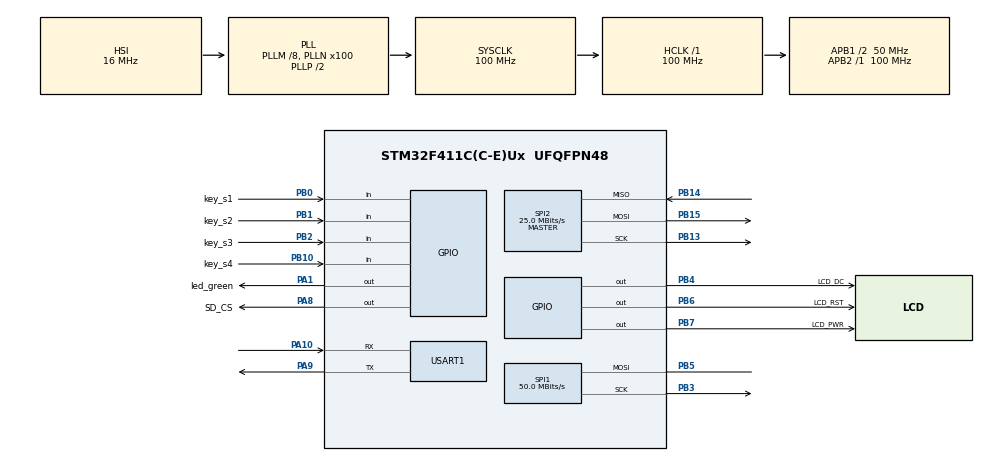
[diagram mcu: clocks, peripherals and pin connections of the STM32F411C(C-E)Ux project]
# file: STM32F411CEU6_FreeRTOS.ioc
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Mcu.Family=STM32F4
Mcu.Name=STM32F411C(C-E)Ux
Mcu.Package=UFQFPN48
NVIC.PriorityGroup=NVIC_PRIORITYGROUP_4
PA1.GPIO_Label=led_green
PA1.Signal=GPIO_Output
PA10.Mode=Asynchronous
PA10.Signal=USART1_RX
PA13.Mode=Serial_Wire
PA13.Signal=SYS_JTMS-SWDIO
PA14.Mode=Serial_Wire
PA14.Signal=SYS_JTCK-SWCLK
PA8.GPIO_Label=SD_CS
PA8.Signal=GPIO_Output
PA9.Mode=Asynchronous
PA9.Signal=USART1_TX
PB0.GPIO_Label=key_s1
PB0.GPIO_PuPd=GPIO_PULLDOWN
PB0.Signal=GPIO_Input
PB1.GPIO_Label=key_s2
PB1.GPIO_PuPd=GPIO_PULLDOWN
PB1.Signal=GPIO_Input
PB10.GPIO_Label=key_s4
PB10.GPIO_PuPd=GPIO_PULLDOWN
PB10.Signal=GPIO_Input
PB13.Mode=Full_Duplex_Master
PB13.Signal=SPI2_SCK
PB14.Mode=Full_Duplex_Master
PB14.Signal=SPI2_MISO
PB15.Mode=Full_Duplex_Master
PB15.Signal=SPI2_MOSI
PB2.GPIO_Label=key_s3
PB2.GPIO_PuPd=GPIO_PULLDOWN
PB2.Signal=GPIO_Input
PB3.Mode=Simplex_Bidirectional_Master
PB3.Signal=SPI1_SCK
PB4.GPIO_Label=LCD_DC
PB4.Signal=GPIO_Output
PB5.Mode=Simplex_Bidirectional_Master
PB5.Signal=SPI1_MOSI
PB6.GPIO_Label=LCD_RST
PB6.Signal=GPIO_Output
PB7.GPIO_Label=LCD_PWR
PB7.Signal=GPIO_Output
PH0\ -\ OSC_IN.Mode=HSE-External-Oscillator
PH0\ -\ OSC_IN.Signal=RCC_OSC_IN
PH1\ -\ OSC_OUT.Mode=HSE-External-Oscillator
PH1\ -\ OSC_OUT.Signal=RCC_OSC_OUT
ProjectManager.HeapSize=0x200
ProjectManager.StackSize=0x400
ProjectManager.TargetToolchain=MDK-ARM V5.27
RCC.48MHZClocksFreq_Value=50000000
RCC.AHBFreq_Value=100000000
RCC.APB1CLKDivider=RCC_HCLK_DIV2
RCC.APB1Freq_Value=50000000
RCC.APB1TimFreq_Value=100000000
RCC.APB2Freq_Value=100000000
RCC.APB2TimFreq_Value=100000000
RCC.CortexFreq_Value=100000000
RCC.HCLKFreq_Value=100000000
RCC.HSE_VALUE=12000000
RCC.HSI_VALUE=16000000
RCC.LSE_VALUE=32768
RCC.PLLM=8
RCC.PLLN=100
RCC.SYSCLKFreq_VALUE=100000000
RCC.SYSCLKSource=RCC_SYSCLKSOURCE_PLLCLK
RCC.VCOOutputFreq_Value=200000000
SPI1.CLKPhase=SPI_PHASE_2EDGE
SPI1.CLKPolarity=SPI_POLARITY_HIGH
SPI1.CalculateBaudRate=50.0 MBits/s
SPI1.Direction=SPI_DIRECTION_1LINE
SPI1.Mode=SPI_MODE_MASTER
SPI1.VirtualType=VM_MASTER
SPI2.CalculateBaudRate=25.0 MBits/s
SPI2.Direction=SPI_DIRECTION_2LINES
SPI2.Mode=SPI_MODE_MASTER
SPI2.VirtualType=VM_MASTER
USART1.VirtualMode=VM_ASYNC
board=custom

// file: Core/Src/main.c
/* USER CODE BEGIN Header */
/**
  ******************************************************************************
  * @file           : main.c
  * @brief          : Main program body
  ******************************************************************************
  * @attention
  *
  * Copyright (c) 2023 STMicroelectronics.
  * All rights reserved.
  *
  * This software is licensed under terms that can be found in the LICENSE file
  * in the root directory of this software component.
  * If no LICENSE file comes with this software, it is provided AS-IS.
  *
  ******************************************************************************
  */
/* USER CODE END Header */
#include "main.h"
#include "spi.h"
#include "usart.h"
#include "gpio.h"

void SystemClock_Config(void);

int main(void)
{

  /* MCU Configuration--------------------------------------------------------*/

  /* Reset of all peripherals, Initializes the Flash interface and the Systick. */
  HAL_Init();

  /* Configure the system clock */
  SystemClock_Config();

  /* Initialize all configured peripherals */
  MX_GPIO_Init();
  MX_USART1_UART_Init();
  MX_SPI1_Init();
  MX_SPI2_Init();
  /* USER CODE BEGIN 2 */

	printf("ok!\r\n");

	LCD_Init();

// 	while(SD_Init())		//检测不到SD卡
//	{
//		printf("SD Card Error!\r\n");
//		HAL_Delay(500);
//		printf("Please Check! \r\n");
//		HAL_Delay(500);
//	}
//	printf("SD Card OK    ");
//	uint32_t sd_size=SD_GetSectorCount();//得到扇区数
//	printf("SD Card Size:%5d MB",sd_size>>11);
//	printf("\r\n\r\n");
  /* USER CODE END 2 */

  /* Infinite loop */
  /* USER CODE BEGIN WHILE */
  while (1)
  {
		uint8_t key = Get_key_with_undo(50);
		if(key != key_null)
		{
			static uint8_t i = 0;
			i++;
			if(i > 21) i = 0;
			LCD_Clear(color_buf[i]);
			printf("i = %d\r\n",i);
		}
    /* USER CODE END WHILE */

  }
}

void SystemClock_Config(void)
{
  RCC_OscInitTypeDef RCC_OscInitStruct = {0};
  RCC_ClkInitTypeDef RCC_ClkInitStruct = {0};

  /** Configure the main internal regulator output voltage
  */
  __HAL_RCC_PWR_CLK_ENABLE();
  __HAL_PWR_VOLTAGESCALING_CONFIG(PWR_REGULATOR_VOLTAGE_SCALE1);

  /** Initializes the RCC Oscillators according to the specified parameters
  * in the RCC_OscInitTypeDef structure.
  */
  RCC_OscInitStruct.OscillatorType = RCC_OSCILLATORTYPE_HSI;
  RCC_OscInitStruct.HSIState = RCC_HSI_ON;
  RCC_OscInitStruct.HSICalibrationValue = RCC_HSICALIBRATION_DEFAULT;
  RCC_OscInitStruct.PLL.PLLState = RCC_PLL_ON;
  RCC_OscInitStruct.PLL.PLLSource = RCC_PLLSOURCE_HSI;
  RCC_OscInitStruct.PLL.PLLM = 8;
  RCC_OscInitStruct.PLL.PLLN = 100;
  RCC_OscInitStruct.PLL.PLLP = RCC_PLLP_DIV2;
  RCC_OscInitStruct.PLL.PLLQ = 4;
  if (HAL_RCC_OscConfig(&RCC_OscInitStruct) != HAL_OK)
  {
    Error_Handler();
  }

  /** Initializes the CPU, AHB and APB buses clocks
  */
  RCC_ClkInitStruct.ClockType = RCC_CLOCKTYPE_HCLK|RCC_CLOCKTYPE_SYSCLK
                              |RCC_CLOCKTYPE_PCLK1|RCC_CLOCKTYPE_PCLK2;
  RCC_ClkInitStruct.SYSCLKSource = RCC_SYSCLKSOURCE_PLLCLK;
  RCC_ClkInitStruct.AHBCLKDivider = RCC_SYSCLK_DIV1;
  RCC_ClkInitStruct.APB1CLKDivider = RCC_HCLK_DIV2;
  RCC_ClkInitStruct.APB2CLKDivider = RCC_HCLK_DIV1;

  if (HAL_RCC_ClockConfig(&RCC_ClkInitStruct, FLASH_LATENCY_3) != HAL_OK)
  {
    Error_Handler();
  }
}

void Error_Handler(void)
{
  /* USER CODE BEGIN Error_Handler_Debug */
  /* User can add his own implementation to report the HAL error return state */
  __disable_irq();
  while (1)
  {
		printf("Error Hander!\r\n");
  }
  /* USER CODE END Error_Handler_Debug */
}
